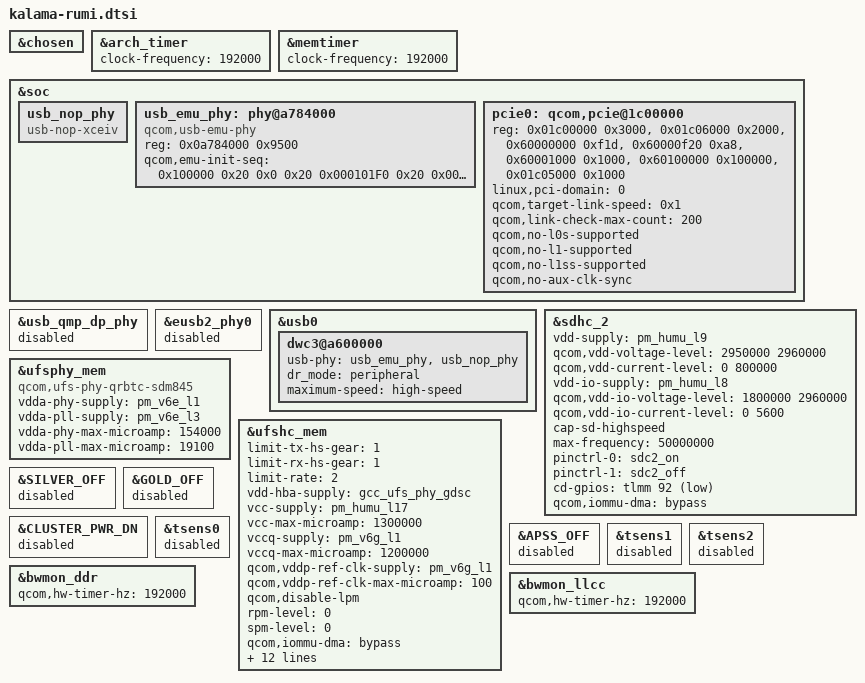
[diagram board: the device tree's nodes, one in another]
#include <dt-bindings/gpio/gpio.h>
#include <dt-bindings/clock/qcom,gcc-kalama.h>
#include <dt-bindings/clock/qcom,rpmh.h>

#include "kalama-pmic-overlay.dtsi"

&chosen {
};

&arch_timer {
	clock-frequency = <192000>;
};

&memtimer {
	clock-frequency = <192000>;
};

&soc {
	#address-cells = <1>;
	#size-cells = <1>;

	usb_nop_phy: usb_nop_phy {
		compatible = "usb-nop-xceiv";
	};

	usb_emu_phy: phy@a784000 {
		compatible = "qcom,usb-emu-phy";
		reg = <0x0a784000 0x9500>;

		qcom,emu-init-seq = <0x100000 0x20
		     0x0 0x20
		     0x000101F0 0x20
		     0x00100000 0x3c
		     0x0 0x3c
		     0x0010060 0x3c>;
	};

	pcie0: qcom,pcie@1c00000 {
		reg = <0x01c00000 0x3000>,
			<0x01c06000 0x2000>,
			<0x60000000 0xf1d>,
			<0x60000f20 0xa8>,
			<0x60001000 0x1000>,
			<0x60100000 0x100000>,
			<0x01c05000 0x1000>;
			reg-names = "parf", "phy", "dm_core", "elbi", "iatu", "conf",
				"rumi";

			linux,pci-domain = <0>;
			qcom,target-link-speed = <0x1>;
			qcom,link-check-max-count = <200>; /* 1 sec */
			qcom,no-l0s-supported;
			qcom,no-l1-supported;
			qcom,no-l1ss-supported;
			qcom,no-aux-clk-sync;

		status = "ok";
	};
};

&usb_qmp_dp_phy {
	status = "disabled";
};

&eusb2_phy0 {
	status = "disabled";
};

&usb0 {
	dwc3@a600000 {
		usb-phy = <&usb_emu_phy>, <&usb_nop_phy>;
		dr_mode = "peripheral";
		maximum-speed = "high-speed";
	};
};

&sdhc_2 {
	status = "ok";
	vdd-supply = <&pm_humu_l9>;
	qcom,vdd-voltage-level = <2950000 2960000>;
	qcom,vdd-current-level = <0 800000>;

	vdd-io-supply = <&pm_humu_l8>;
	qcom,vdd-io-voltage-level = <1800000 2960000>;
	qcom,vdd-io-current-level = <0 5600>;

	cap-sd-highspeed;
	max-frequency = <50000000>;

	pinctrl-names = "default", "sleep";
	pinctrl-0 = <&sdc2_on>;
	pinctrl-1 = <&sdc2_off>;

	cd-gpios = <&tlmm 92 GPIO_ACTIVE_LOW>;

	qcom,iommu-dma = "bypass";
};

&ufsphy_mem {
	compatible = "qcom,ufs-phy-qrbtc-sdm845";

	vdda-phy-supply = <&pm_v6e_l1>;
	vdda-pll-supply = <&pm_v6e_l3>;
	vdda-phy-max-microamp = <154000>;
	vdda-pll-max-microamp = <19100>;

	status = "ok";
};

&ufshc_mem {
	limit-tx-hs-gear = <1>;
	limit-rx-hs-gear = <1>;
	limit-rate = <2>; /* HS Rate-B */

	vdd-hba-supply = <&gcc_ufs_phy_gdsc>;

	vcc-supply = <&pm_humu_l17>;
	vcc-max-microamp = <1300000>;

	vccq-supply = <&pm_v6g_l1>;
	vccq-max-microamp = <1200000>;

	qcom,vddp-ref-clk-supply = <&pm_v6g_l1>;
	qcom,vddp-ref-clk-max-microamp = <100>;

	qcom,disable-lpm;
	rpm-level = <0>;
	spm-level = <0>;

	qcom,iommu-dma = "bypass";

	clock-names =
		"core_clk",
		"bus_aggr_clk",
		"iface_clk",
		"core_clk_unipro",
		"core_clk_ice",
		"ref_clk",
		"tx_lane0_sync_clk",
		"rx_lane0_sync_clk",
		"rx_lane1_sync_clk";
	clocks =
		<&gcc GCC_UFS_PHY_AXI_CLK>,
		<&gcc GCC_AGGRE_UFS_PHY_AXI_CLK>,
		<&gcc GCC_UFS_PHY_AHB_CLK>,
		<&gcc GCC_UFS_PHY_UNIPRO_CORE_CLK>,
		<&gcc GCC_UFS_PHY_ICE_CORE_CLK>,
		<&rpmhcc RPMH_CXO_CLK>,
		<&gcc GCC_UFS_PHY_TX_SYMBOL_0_CLK>,
		<&gcc GCC_UFS_PHY_RX_SYMBOL_0_CLK>,
		<&gcc GCC_UFS_PHY_RX_SYMBOL_1_CLK>;
	freq-table-hz =
		<75000000 300000000>,
		<0 0>,
		<0 0>,
		<75000000 300000000>,
		<100000000 403000000>,
		<0 0>,
		<0 0>,
		<0 0>,
		<0 0>;

	status = "ok";
};

&SILVER_OFF {
	status = "nok";
};

&GOLD_OFF {
	status = "nok";
};

&CLUSTER_PWR_DN {
	status = "nok";
};

&APSS_OFF {
	status = "nok";
};

&tsens0 {
	status = "disabled";
};

&tsens1 {
	status = "disabled";
};

&tsens2 {
	status = "disabled";
};

&bwmon_ddr {
	qcom,hw-timer-hz = <192000>;
};

&bwmon_llcc {
	qcom,hw-timer-hz = <192000>;
};
